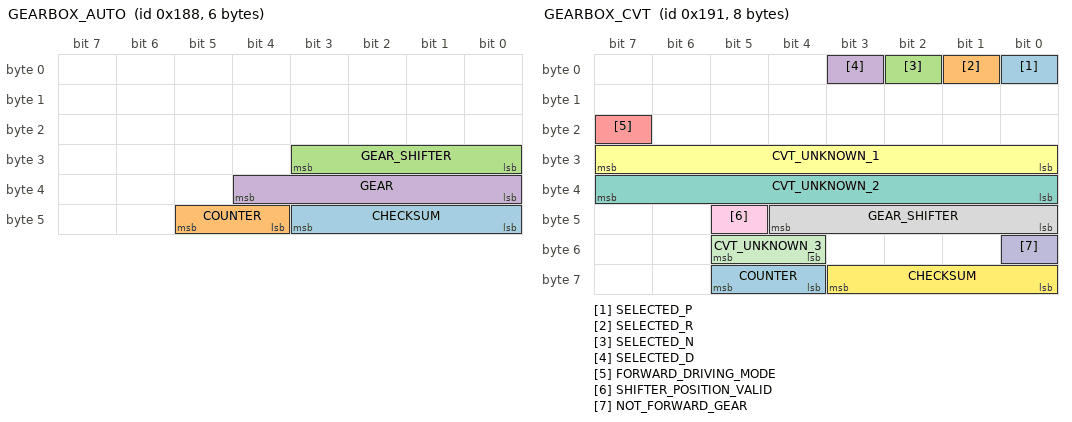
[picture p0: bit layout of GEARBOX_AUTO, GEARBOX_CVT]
BO_ 392 GEARBOX_AUTO: 6 XXX
 SG_ CHECKSUM : 43|4@0+ (1,0) [0|15] "" XXX
 SG_ COUNTER : 45|2@0+ (1,0) [0|3] "" XXX
 SG_ GEAR_SHIFTER : 27|4@0+ (1,0) [0|15] "" EON
 SG_ GEAR : 36|5@0+ (1,0) [0|31] "" EON

BO_ 401 GEARBOX_CVT: 8 PCM
 SG_ SELECTED_P : 0|1@0+ (1,0) [0|1] "" XXX
 SG_ SELECTED_R : 1|1@0+ (1,0) [0|1] "" XXX
 SG_ SELECTED_N : 2|1@0+ (1,0) [0|1] "" XXX
 SG_ SELECTED_D : 3|1@0+ (1,0) [0|1] "" XXX
 SG_ FORWARD_DRIVING_MODE : 23|1@0+ (1,0) [0|1] "" XXX
 SG_ CVT_UNKNOWN_1 : 31|8@0+ (1,0) [0|255] "" XXX
 SG_ CVT_UNKNOWN_2 : 39|8@0+ (1,0) [0|255] "" XXX
 SG_ GEAR_SHIFTER : 44|5@0+ (1,0) [0|31] "" XXX
 SG_ SHIFTER_POSITION_VALID : 45|1@0+ (1,0) [0|1] "" XXX
 SG_ NOT_FORWARD_GEAR : 48|1@0+ (1,0) [0|1] "" XXX
 SG_ CVT_UNKNOWN_3 : 53|2@0+ (1,0) [0|3] "" XXX
 SG_ CHECKSUM : 59|4@0+ (1,0) [0|15] "" EON
 SG_ COUNTER : 61|2@0+ (1,0) [0|3] "" EON

VAL_ 392 GEAR_SHIFTER 1 "P" 2 "R" 4 "N" 8 "D" ;
VAL_ 392 GEAR 26 "S" 4 "D" 3 "N" 2 "R" 1 "P" ;

CM_ SG_ 392 GEAR_SHIFTER "One-hot lever position: P=1, R=2, N=4, D=8. Raw 0 is AMBIGUOUS --
it means BOTH Sport AND the lever passing BETWEEN detents, confirmed by the owner of a 2015
Accord (HONDA_ELESYS). That is why 0 has no VAL entry here: a decoder that maps it straight
to Sport emits a phantom Sport on every single shift. Measured over 473k frames, every 0 run
in that recording was a transient -- 47 of them, median 3 frames (30 ms), max 520 ms, all
below 0.5 m/s -- because Sport was never selected during it. Only DURATION separates the two
cases, so carstate.py resolves it with a 1.0 s dwell (see update_gear_elesys). GEAR (36|5)
carries 26 for Sport and is the fast path: measured over 86 routes (1406 min), the frames with
GEAR_SHIFTER 0 read GEAR 26 on 16,164 frames (the S selections) and GEAR 0 on 2,975 (the shift
transients), so the dwell is only the fallback.";

CM_ SG_ 401 CVT_UNKNOWN_1 "Probably measured/actual CVT ratio";
CM_ SG_ 401 CVT_UNKNOWN_2 "Probably target/commanded CVT ratio";
VAL_ 401 GEAR_SHIFTER 1 "P" 2 "R" 3 "N" 4 "D" 7 "L" 10 "S";
